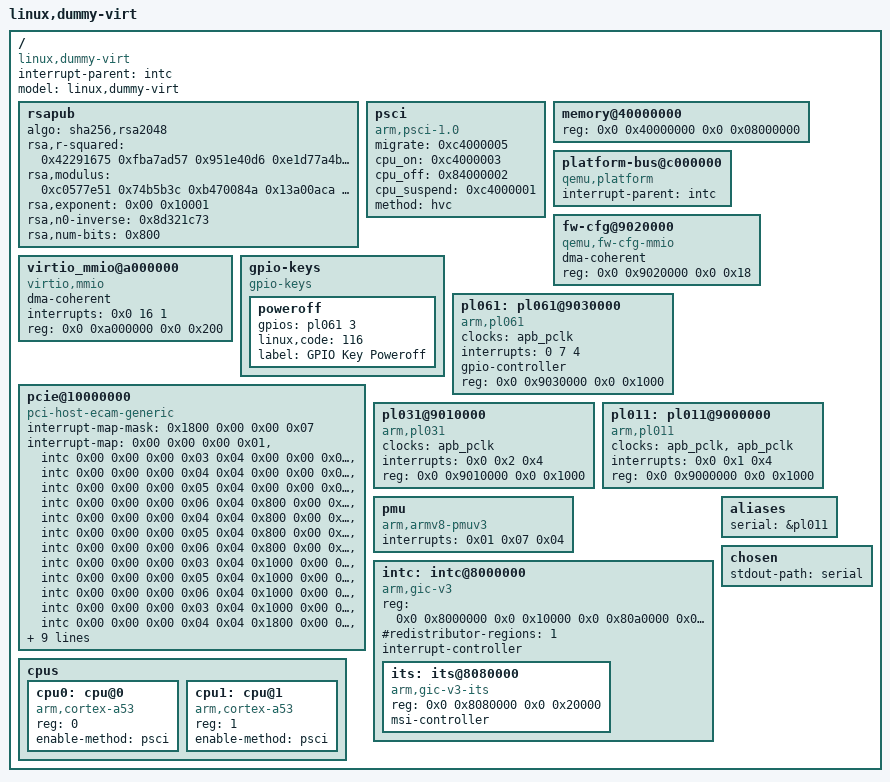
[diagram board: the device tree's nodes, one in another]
/dts-v1/;

/ {
	interrupt-parent = <&intc>;
	model = "linux,dummy-virt";
	#size-cells = <2>;
	#address-cells = <2>;
	compatible = "linux,dummy-virt";

	rsapub {
		algo = "sha256,rsa2048";
        rsa,r-squared = <0x42291675 0xfba7ad57 0x951e40d6 0xe1d77a4b 0xb876169 0xda01668f 0x6b0e7b21 0x402a6277 0x85aaae6 0x541cba5d 0x6c63938c 0x706e284a 0x884eedc6 0x544c6184 0x61574e8b 0xe1440c5e 0xfa55426c 0x84de5d70 0x735feb0a 0x511f48cd 0x3fe37c8d 0x6fc897e7 0xcdd1967a 0x11651d19 0xd6e69ac7 0xb2836dd1 0x1dffaa85 0x61cf414a 0x1b58f118 0x969a0c15 0x67282a21 0x3ae38725 0xe0c8ae4a 0xa0735297 0x4c19c53c 0xf7a9305a 0xcbb1d91c 0x78360bac 0x69a9125c 0x1685c3c5 0xf1dab6db 0x42d9c3e6 0x73eef336 0x6a961a95 0xa9602b6d 0x8248bed8 0xe34326f4 0x6738dde 0x8d20da1f 0xe6323617 0xb4d6fc40 0x89620fb8 0xc707e56 0x87538c07 0x7acf09bc 0x18daf28f 0xec2912e4 0xe69d3ff6 0xdeeea516 0xe62ff0ad 0x2c811f86 0x327f3760 0x11851753 0x1bfaf5a2>;
        rsa,modulus = <0xc0577e51 0x74b5b3c 0xb470084a 0x13a00aca 0x35384425 0xc37b3ac3 0x6ac0cc6a 0x5a0d6b7e 0xf8d0c782 0xad3eb351 0xbf1e8001 0xac653614 0x8de0a03e 0xb3254ea2 0x81a499e 0x7c0eda0 0x385da0b0 0x5f371466 0x2e7047bf 0xbe0d30fc 0x2e3dca50 0xde56b533 0x4febe14c 0xaebf3161 0x17163fd 0xf09cab8c 0xeb736f96 0xe0320f59 0x1d1b88a 0x72a3fa54 0xa87b4be4 0x1ced7b60 0xd358f377 0x708b97a9 0xcac81717 0x64b7eb95 0xd27ae7ef 0x68a60d8c 0x15835c32 0xfe17131c 0xdab80b9e 0x73ec4c58 0x75adaf80 0x573784ff 0xbf422a0e 0x972b7f2a 0xcc97f5b1 0x7e99f775 0xa600b517 0x2c8538d4 0x1c76cc36 0x76b07d3b 0x7a458a21 0xd0e1a773 0xd16d47b0 0x4e14373f 0x61a0d01d 0x1c9ed535 0x7a933ae0 0x271d53a9 0x7b4b60c4 0xc381ec74 0x771a8395 0xff501745>;
        rsa,exponent = <0x00 0x10001>;
        rsa,n0-inverse = <0x8d321c73>;
        rsa,num-bits = <0x800>;
	};

	psci {
		migrate = <0xc4000005>;
		cpu_on = <0xc4000003>;
		cpu_off = <0x84000002>;
		cpu_suspend = <0xc4000001>;
		method = "hvc";
		compatible = "arm,psci-1.0", "arm,psci-0.2", "arm,psci";
	};

	memory@40000000 {
		reg = <0x0 0x40000000 0x0 0x08000000>;
		device_type = "memory";
	};

	platform-bus@c000000 {
		interrupt-parent = <&intc>;
		ranges = <0x0 0x0 0xc000000 0x2000000>;
		#address-cells = <1>;
		#size-cells = <1>;
		compatible = "qemu,platform", "simple-bus";
	};

	fw-cfg@9020000 {
		dma-coherent;
		reg = <0x0 0x9020000 0x0 0x18>;
		compatible = "qemu,fw-cfg-mmio";
	};

	virtio_mmio@a000000 {
		dma-coherent;
		interrupts = <0x0 16 1>;
		reg = <0x0 0xa000000 0x0 0x200>;
		compatible = "virtio,mmio";
	};

	gpio-keys {
		compatible = "gpio-keys";

		poweroff {
			gpios = <&pl061 3 0>;
			linux,code = <116>;
			label = "GPIO Key Poweroff";
		};
	};

	pl061: pl061@9030000 {
		clock-names = "apb_pclk";
		clocks = <&apb_pclk>;
		interrupts = <0 7 4>;
		gpio-controller;
		#gpio-cells = <2>;
		compatible = "arm,pl061", "arm,primecell";
		reg = <0x0 0x9030000 0x0 0x1000>;
	};

	pcie@10000000 {
		interrupt-map-mask = <0x1800 0x00 0x00 0x07>;
		interrupt-map = <0x00 0x00 0x00 0x01 &intc 0x00 0x00 0x00 0x03 0x04
			0x00 0x00 0x00 0x02 &intc 0x00 0x00 0x00 0x04 0x04
			0x00 0x00 0x00 0x03 &intc 0x00 0x00 0x00 0x05 0x04
			0x00 0x00 0x00 0x04 &intc 0x00 0x00 0x00 0x06 0x04
			0x800 0x00 0x00 0x01 &intc 0x00 0x00 0x00 0x04 0x04
			0x800 0x00 0x00 0x02 &intc 0x00 0x00 0x00 0x05 0x04
			0x800 0x00 0x00 0x03 &intc 0x00 0x00 0x00 0x06 0x04
			0x800 0x00 0x00 0x04 &intc 0x00 0x00 0x00 0x03 0x04
			0x1000 0x00 0x00 0x01 &intc 0x00 0x00 0x00 0x05 0x04
			0x1000 0x00 0x00 0x02 &intc 0x00 0x00 0x00 0x06 0x04
			0x1000 0x00 0x00 0x03 &intc 0x00 0x00 0x00 0x03 0x04
			0x1000 0x00 0x00 0x04 &intc 0x00 0x00 0x00 0x04 0x04
			0x1800 0x00 0x00 0x01 &intc 0x00 0x00 0x00 0x06 0x04
			0x1800 0x00 0x00 0x02 &intc 0x00 0x00 0x00 0x03 0x04
			0x1800 0x00 0x00 0x03 &intc 0x00 0x00 0x00 0x04 0x04
			0x1800 0x00 0x00 0x04 &intc 0x00 0x00 0x00 0x05 0x04>;
		#interrupt-cells = <0x01>;
		ranges = <0x1000000 0x00 0x00 0x00 0x3eff0000 0x00 0x10000 0x2000000 0x00 0x10000000 0x00 0x10000000 0x00 0x2eff0000 0x3000000 0x80 0x00 0x80 0x00 0x80 0x00>;
		reg = <0x40 0x10000000 0x00 0x10000000>;
		msi-map = <0x00 &its 0x00 0x10000>;
		dma-coherent;
		bus-range = <0x00 0xff>;
		linux,pci-domain = <0x00>;
		#size-cells = <0x02>;
		#address-cells = <0x03>;
		device_type = "pci";
		compatible = "pci-host-ecam-generic";
	};

	pl031@9010000 {
		clock-names = "apb_pclk";
		clocks = <&apb_pclk>;
		interrupts = <0x0 0x2 0x4>;
		reg = <0x0 0x9010000 0x0 0x1000>;
		compatible = "arm,pl031", "arm,primecell";
	};

	pl011: pl011@9000000 {
		clock-names = "uartclk", "apb_pclk";
		clocks = <&apb_pclk &apb_pclk>;
		interrupts = <0x0 0x1 0x4>;
		reg = <0x0 0x9000000 0x0 0x1000>;
		compatible = "arm,pl011", "arm,primecell";
	};

	pmu {
		interrupts = <0x01 0x07 0x04>;
		compatible = "arm,armv8-pmuv3";
	};

	intc: intc@8000000 {
		reg = <0x0 0x8000000 0x0 0x10000 0x0 0x80a0000 0x0 0xf60000>;
		#redistributor-regions = <1>;
		compatible = "arm,gic-v3";
		ranges;
		#size-cells = <2>;
		#address-cells = <2>;
		interrupt-controller;
		#interrupt-cells = <3>;

		its: its@8080000 {
			reg = <0x0 0x8080000 0x0 0x20000>;
			#msi-cells = <1>;
			msi-controller;
			compatible = "arm,gic-v3-its";
		};
	};

	cpus {
		#size-cells = <0>;
		#address-cells = <1>;

		cpu0: cpu@0 {
			reg = <0>;
			enable-method = "psci";
			compatible = "arm,cortex-a53";
			device_type = "cpu";
		};

		cpu1: cpu@1 {
			reg = <1>;
			enable-method = "psci";
			compatible = "arm,cortex-a53";
			device_type = "cpu";
		};
	};

	aliases {
		serial = &pl011;
	};

	chosen {
		stdout-path = "serial";
	};
};
